# cxd5602 register map
Vendor: Sony Semiconductor Solutions; Series: CXD56xx; File version: 1.0
CPU: CM4 r0p1, little endian, MPU, FPU, 3 interrupt priority bits, 144 interrupts
Registers are 32-bit, read-write, reset 0x0 unless marked. A register's access mark holds for its fields unless they carry their own. Offsets are from the block's base; [hi:lo] are bit positions; {n}, {i} and the like mark numbered series; 'fields as' and 'values as' point back to an identical list.

## ADDRCONV — Address Converter
Base 0x02012000
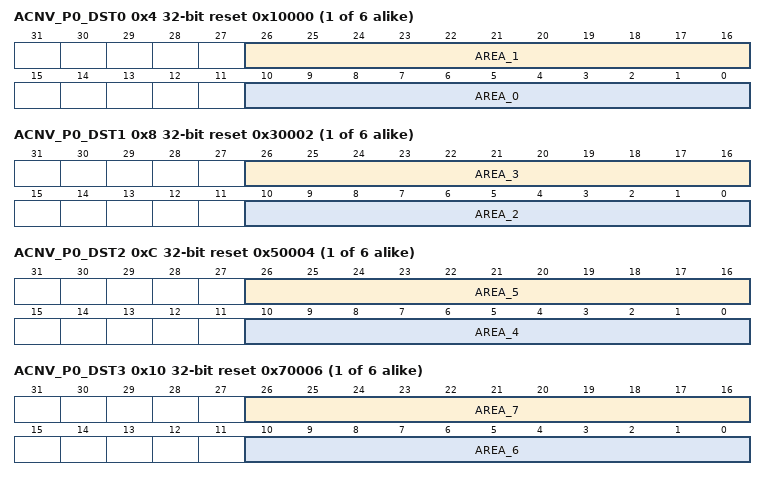
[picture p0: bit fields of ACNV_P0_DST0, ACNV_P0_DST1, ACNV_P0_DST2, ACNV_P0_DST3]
{0x4+0x20*i} ACNV_P{i}_DST0 reset 0x10000 (i=0..5) — CPU {i} address conversion area 0/1
  [26:16] AREA_1 — 0x10000 .. 0x20000
  [10:0] AREA_0 — 0x00000 .. 0x10000
{0x8+0x20*i} ACNV_P{i}_DST1 reset 0x30002 (i=0..5) — CPU {i} address conversion area 2/3
  [26:16] AREA_3 — 0x30000 .. 0x40000
  [10:0] AREA_2 — 0x20000 .. 0x30000
{0xC+0x20*i} ACNV_P{i}_DST2 reset 0x50004 (i=0..5) — CPU {i} address conversion area 4/5
  [26:16] AREA_5 — 0x50000 .. 0x60000
  [10:0] AREA_4 — 0x40000 .. 0x50000
{0x10+0x20*i} ACNV_P{i}_DST3 reset 0x70006 (i=0..5) — CPU {i} address conversion area 6/7
  [26:16] AREA_7 — 0x70000 .. 0x80000
  [10:0] AREA_6 — 0x60000 .. 0x70000
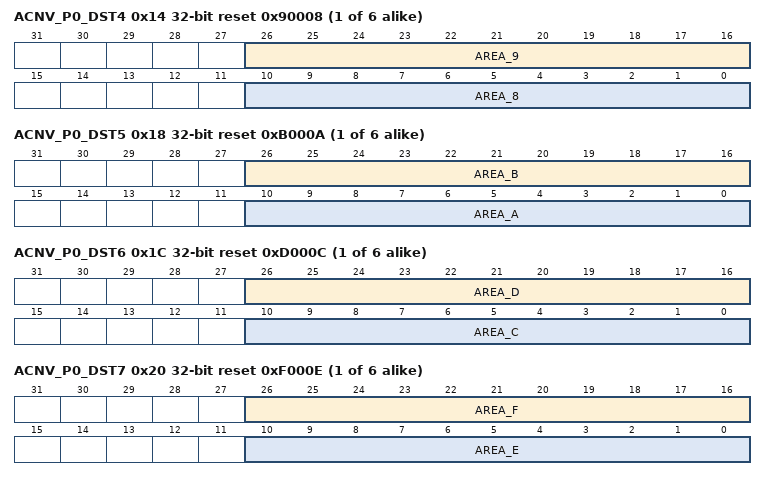
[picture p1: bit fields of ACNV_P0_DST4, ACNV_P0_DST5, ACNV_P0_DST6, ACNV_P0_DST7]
{0x14+0x20*i} ACNV_P{i}_DST4 reset 0x90008 (i=0..5) — CPU {i} address conversion area 8/9
  [26:16] AREA_9 — 0x90000 .. 0xa0000
  [10:0] AREA_8 — 0x80000 .. 0x90000
{0x18+0x20*i} ACNV_P{i}_DST5 reset 0xB000A (i=0..5) — CPU {i} address conversion area A/B
  [26:16] AREA_B — 0xb0000 .. 0xc0000
  [10:0] AREA_A — 0xa0000 .. 0xb0000
{0x1C+0x20*i} ACNV_P{i}_DST6 reset 0xD000C (i=0..5) — CPU {i} address conversion area C/D
  [26:16] AREA_D — 0xd0000 .. 0xe0000
  [10:0] AREA_C — 0xc0000 .. 0xd0000
{0x20+0x20*i} ACNV_P{i}_DST7 reset 0xF000E (i=0..5) — CPU {i} address conversion area E/F
  [26:16] AREA_F — 0xf0000 .. 0x100000
  [10:0] AREA_E — 0xe0000 .. 0xf0000

## GE2D — Hardware 2D Graphics Engine
Base 0x02101000
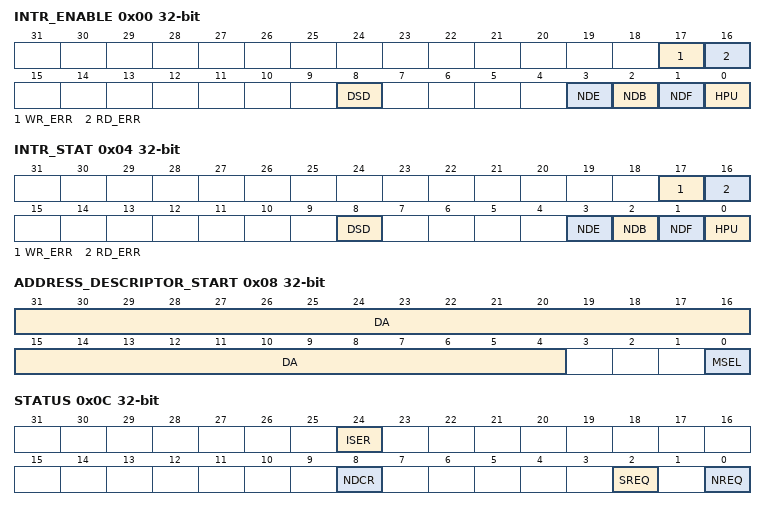
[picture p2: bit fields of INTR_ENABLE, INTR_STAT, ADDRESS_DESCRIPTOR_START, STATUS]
0x00 INTR_ENABLE — 2D Graphics Engine Interrupt Control
  [17] WR_ERR — Write Error Interrupt
  [16] RD_ERR — Read Error Interrupt
  [8] DSD — Descriptor STOP Command Done Interrupt
  [3] NDE — Normal Descriptor Command Error Interrupt
  [2] NDB — Normal Descriptor Command Branch Interrupt
  [1] NDF — Normal Descriptor Command Finished Interrupt
  [0] HPU — Normal Descriptor Command Update Interrupt
0x04 INTR_STAT write-1-clears — 2D Graphics Engine Interrupt Status and Clear
  fields as INTR_ENABLE
0x08 ADDRESS_DESCRIPTOR_START — Descriptor Address Set Register
  [31:4] DA — Descriptor Address
  [0] MSEL — must be 1
0x0C STATUS ro
  [24] ISER — ISE Running Status
  [8] NDCR — Normal Descriptor Command Running Status
  [2] SREQ — Reqesting Descriptor Stop
  [0] NREQ — Requesting Normal Descriptor
0x0C CMD_DESCRIPTOR wo — Command Register
  [1:0] COMMAND
    0=NOP (No Operation); 1=RUN (Normal Descriptor Set and Run); 3=STOP (Stop Descriptor)
0x10 STAT_NORMAL_DESCRIPTOR_ADDRESS ro — Normal Descriptor Address Register
0x14 STAT_CURRENT_DESCRIPTOR_ADDRESS ro — Current Descriptor Address Register

## ROT — Image rotation
Base 0x02101400
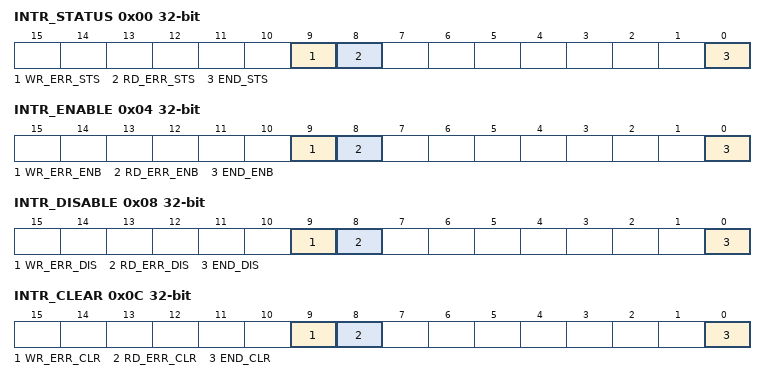
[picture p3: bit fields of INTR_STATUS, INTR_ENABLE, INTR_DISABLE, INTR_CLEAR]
0x00 INTR_STATUS ro — Interrupt Status
  [9] WR_ERR_STS — Write Error
  [8] RD_ERR_STS — Read Error
  [0] END_STS — Done
0x04 INTR_ENABLE — Interrupt Enable
  [all] fields
    0=Disable; 1=Enable
  [9] WR_ERR_ENB — Write Error Enable
  [8] RD_ERR_ENB — Read Error
  [0] END_ENB — Done Interrupt Enable
0x08 INTR_DISABLE wo — Interrupt Disable
  [9] WR_ERR_DIS write-1-sets — Write Error Disable
  [8] RD_ERR_DIS write-1-sets — Read Error Disable
  [0] END_DIS write-1-sets — Done Interrupt Disable
0x0C INTR_CLEAR wo — Interrupt Clear
  [9] WR_ERR_CLR write-1-sets — Write Error Clear
  [8] RD_ERR_CLR write-1-sets — Read Error Clear
  [0] END_CLR write-1-sets — Done Interrupt Clear
0x10 COMMAND wo — Start rotation processing
  [0] CMD — Start rotation
    1=start
0x14 SET_DIRECTION — Set Rotation Angle
  [2:0] ROT — Rotation Angle
    0=No rotation; 1=Right 90 degrees; 2=Right 180 degrees; 4=Right 270 degrees
0x18 SET_SRC_HSIZE — Source Image Horizontal Size (Actual size - 1)
  [11:0] SIZE
0x1C SET_SRC_VSIZE — Source Image Vertical Size (Actual size - 1)
  [11:0] SIZE
0x20 SET_SRC_ADDRESS — Source Image Address
0x24 SET_SRC_PITCH — Source Image Pitch (Actual size - 1)
  [11:0] PITCH
0x28 SET_DST_ADDRESS — Destination Address
0x2C SET_DST_PITCH — Destination Image Pitch (Actual size - 1)
  [11:0] PITCH
0x30 STATUS ro — Running Status
  [0] STATUS — Running Status (1 = running)
    0=stop; 1=running
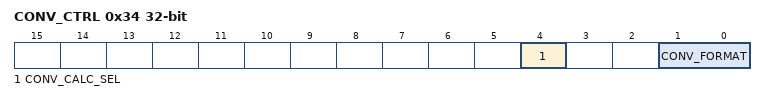
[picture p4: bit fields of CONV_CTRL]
0x34 CONV_CTRL — Color Convertion Control
  [4] CONV_CALC_SEL — Scale factor for Cb and Cr
    0=FROM16TO240range; 1=FROM-127TO127range
  [1:0] CONV_FORMAT — Convert RGB565 to YCbCr422
    0=NOCONVERT; 1=YCBCR422_RGB565; 2=RGB565_YCBCR422
0x38 RGB_ALIGNMENT — RGB format selector
  [0] FORMAT — RGB Format
    0=RGB; 1=BGR
